# STM32H7B3x register map
File version: 2.2
CPU: CM7 r0p1, little endian, MPU, FPU, 4 interrupt priority bits
Registers are 32-bit, read-write, reset 0x0 unless marked. A register's access mark holds for its fields unless they carry their own. Offsets are from the block's base; [hi:lo] are bit positions; lines under a group give offsets from that group; {n}, {i} and the like mark numbered series; 'fields as' and 'values as' point back to an identical list; <NAME> marks a mode.

## DMA1 — DMA controller
Base 0x40020000
Same registers: DMA2 0x40020400
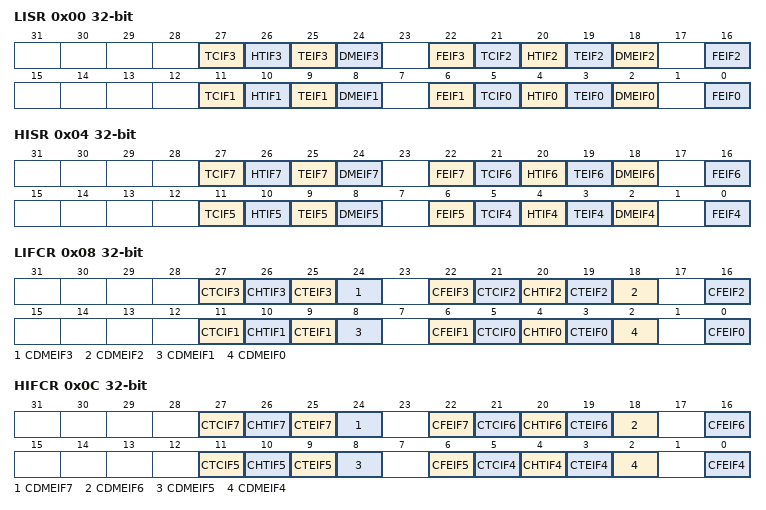
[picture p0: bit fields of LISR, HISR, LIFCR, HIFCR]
0x00 LISR ro — low interrupt status register
  [27] TCIF3 — Stream x transfer complete interrupt flag (x = 3..0)
    on read: 0=NotComplete (No transfer complete event on stream x); 1=Complete (A transfer complete event occurred on stream x)
  [26] HTIF3 — Stream x half transfer interrupt flag (x=3..0)
    on read: 0=NotHalf (No half transfer event on stream x); 1=Half (A half transfer event occurred on stream x)
  [25] TEIF3 — Stream x transfer error interrupt flag (x=3..0)
    on read: 0=NoError (No transfer error on stream x); 1=Error (A transfer error occurred on stream x)
  [24] DMEIF3 — Stream x direct mode error interrupt flag (x=3..0)
    on read: 0=NoError (No Direct Mode error on stream x); 1=Error (A Direct Mode error occurred on stream x)
  [22] FEIF3 — Stream x FIFO error interrupt flag (x=3..0)
    on read: 0=NoError (No FIFO error event on stream x); 1=Error (A FIFO error event occurred on stream x)
  [21] TCIF2 — Stream x transfer complete interrupt flag (x = 3..0)
    values as TCIF3
  [20] HTIF2 — Stream x half transfer interrupt flag (x=3..0)
    values as HTIF3
  [19] TEIF2 — Stream x transfer error interrupt flag (x=3..0)
    values as TEIF3
  [18] DMEIF2 — Stream x direct mode error interrupt flag (x=3..0)
    values as DMEIF3
  [16] FEIF2 — Stream x FIFO error interrupt flag (x=3..0)
    values as FEIF3
  [11] TCIF1 — Stream x transfer complete interrupt flag (x = 3..0)
    values as TCIF3
  [10] HTIF1 — Stream x half transfer interrupt flag (x=3..0)
    values as HTIF3
  [9] TEIF1 — Stream x transfer error interrupt flag (x=3..0)
    values as TEIF3
  [8] DMEIF1 — Stream x direct mode error interrupt flag (x=3..0)
    values as DMEIF3
  [6] FEIF1 — Stream x FIFO error interrupt flag (x=3..0)
    values as FEIF3
  [5] TCIF0 — Stream x transfer complete interrupt flag (x = 3..0)
    values as TCIF3
  [4] HTIF0 — Stream x half transfer interrupt flag (x=3..0)
    values as HTIF3
  [3] TEIF0 — Stream x transfer error interrupt flag (x=3..0)
    values as TEIF3
  [2] DMEIF0 — Stream x direct mode error interrupt flag (x=3..0)
    values as DMEIF3
  [0] FEIF0 — Stream x FIFO error interrupt flag (x=3..0)
    values as FEIF3
0x04 HISR ro — high interrupt status register
  [27] TCIF7 — Stream x transfer complete interrupt flag (x=7..4)
    values as LISR.TCIF3
  [26] HTIF7 — Stream x half transfer interrupt flag (x=7..4)
    values as LISR.HTIF3
  [25] TEIF7 — Stream x transfer error interrupt flag (x=7..4)
    values as LISR.TEIF3
  [24] DMEIF7 — Stream x direct mode error interrupt flag (x=7..4)
    values as LISR.DMEIF3
  [22] FEIF7 — Stream x FIFO error interrupt flag (x=7..4)
    values as LISR.FEIF3
  [21] TCIF6 — Stream x transfer complete interrupt flag (x=7..4)
    values as LISR.TCIF3
  [20] HTIF6 — Stream x half transfer interrupt flag (x=7..4)
    values as LISR.HTIF3
  [19] TEIF6 — Stream x transfer error interrupt flag (x=7..4)
    values as LISR.TEIF3
  [18] DMEIF6 — Stream x direct mode error interrupt flag (x=7..4)
    values as LISR.DMEIF3
  [16] FEIF6 — Stream x FIFO error interrupt flag (x=7..4)
    values as LISR.FEIF3
  [11] TCIF5 — Stream x transfer complete interrupt flag (x=7..4)
    values as LISR.TCIF3
  [10] HTIF5 — Stream x half transfer interrupt flag (x=7..4)
    values as LISR.HTIF3
  [9] TEIF5 — Stream x transfer error interrupt flag (x=7..4)
    values as LISR.TEIF3
  [8] DMEIF5 — Stream x direct mode error interrupt flag (x=7..4)
    values as LISR.DMEIF3
  [6] FEIF5 — Stream x FIFO error interrupt flag (x=7..4)
    values as LISR.FEIF3
  [5] TCIF4 — Stream x transfer complete interrupt flag (x=7..4)
    values as LISR.TCIF3
  [4] HTIF4 — Stream x half transfer interrupt flag (x=7..4)
    values as LISR.HTIF3
  [3] TEIF4 — Stream x transfer error interrupt flag (x=7..4)
    values as LISR.TEIF3
  [2] DMEIF4 — Stream x direct mode error interrupt flag (x=7..4)
    values as LISR.DMEIF3
  [0] FEIF4 — Stream x FIFO error interrupt flag (x=7..4)
    values as LISR.FEIF3
0x08 LIFCR wo — low interrupt flag clear register
  [27] CTCIF3 — Stream x clear transfer complete interrupt flag (x = 3..0)
    on write: 1=Clear the corresponding TCIFx flag
  [26] CHTIF3 — Stream x clear half transfer interrupt flag (x = 3..0)
    on write: 1=Clear the corresponding HTIFx flag
  [25] CTEIF3 — Stream x clear transfer error interrupt flag (x = 3..0)
    on write: 1=Clear the corresponding TEIFx flag
  [24] CDMEIF3 — Stream x clear direct mode error interrupt flag (x = 3..0)
    on write: 1=Clear the corresponding DMEIFx flag
  [22] CFEIF3 — Stream x clear FIFO error interrupt flag (x = 3..0)
    on write: 1=Clear the corresponding CFEIFx flag
  [21] CTCIF2 — Stream x clear transfer complete interrupt flag (x = 3..0)
    on write: 1=Clear the corresponding TCIFx flag
  [20] CHTIF2 — Stream x clear half transfer interrupt flag (x = 3..0)
    on write: 1=Clear the corresponding HTIFx flag
  [19] CTEIF2 — Stream x clear transfer error interrupt flag (x = 3..0)
    on write: 1=Clear the corresponding TEIFx flag
  [18] CDMEIF2 — Stream x clear direct mode error interrupt flag (x = 3..0)
    on write: 1=Clear the corresponding DMEIFx flag
  [16] CFEIF2 — Stream x clear FIFO error interrupt flag (x = 3..0)
    on write: 1=Clear the corresponding CFEIFx flag
  [11] CTCIF1 — Stream x clear transfer complete interrupt flag (x = 3..0)
    on write: 1=Clear the corresponding TCIFx flag
  [10] CHTIF1 — Stream x clear half transfer interrupt flag (x = 3..0)
    on write: 1=Clear the corresponding HTIFx flag
  [9] CTEIF1 — Stream x clear transfer error interrupt flag (x = 3..0)
    on write: 1=Clear the corresponding TEIFx flag
  [8] CDMEIF1 — Stream x clear direct mode error interrupt flag (x = 3..0)
    on write: 1=Clear the corresponding DMEIFx flag
  [6] CFEIF1 — Stream x clear FIFO error interrupt flag (x = 3..0)
    on write: 1=Clear the corresponding CFEIFx flag
  [5] CTCIF0 — Stream x clear transfer complete interrupt flag (x = 3..0)
    on write: 1=Clear the corresponding TCIFx flag
  [4] CHTIF0 — Stream x clear half transfer interrupt flag (x = 3..0)
    on write: 1=Clear the corresponding HTIFx flag
  [3] CTEIF0 — Stream x clear transfer error interrupt flag (x = 3..0)
    on write: 1=Clear the corresponding TEIFx flag
  [2] CDMEIF0 — Stream x clear direct mode error interrupt flag (x = 3..0)
    on write: 1=Clear the corresponding DMEIFx flag
  [0] CFEIF0 — Stream x clear FIFO error interrupt flag (x = 3..0)
    on write: 1=Clear the corresponding CFEIFx flag
0x0C HIFCR wo — high interrupt flag clear register
  [27] CTCIF7 — Stream x clear transfer complete interrupt flag (x = 7..4)
    on write: 1=Clear the corresponding TCIFx flag
  [26] CHTIF7 — Stream x clear half transfer interrupt flag (x = 7..4)
    on write: 1=Clear the corresponding HTIFx flag
  [25] CTEIF7 — Stream x clear transfer error interrupt flag (x = 7..4)
    on write: 1=Clear the corresponding TEIFx flag
  [24] CDMEIF7 — Stream x clear direct mode error interrupt flag (x = 7..4)
    on write: 1=Clear the corresponding DMEIFx flag
  [22] CFEIF7 — Stream x clear FIFO error interrupt flag (x = 7..4)
    on write: 1=Clear the corresponding CFEIFx flag
  [21] CTCIF6 — Stream x clear transfer complete interrupt flag (x = 7..4)
    on write: 1=Clear the corresponding TCIFx flag
  [20] CHTIF6 — Stream x clear half transfer interrupt flag (x = 7..4)
    on write: 1=Clear the corresponding HTIFx flag
  [19] CTEIF6 — Stream x clear transfer error interrupt flag (x = 7..4)
    on write: 1=Clear the corresponding TEIFx flag
  [18] CDMEIF6 — Stream x clear direct mode error interrupt flag (x = 7..4)
    on write: 1=Clear the corresponding DMEIFx flag
  [16] CFEIF6 — Stream x clear FIFO error interrupt flag (x = 7..4)
    on write: 1=Clear the corresponding CFEIFx flag
  [11] CTCIF5 — Stream x clear transfer complete interrupt flag (x = 7..4)
    on write: 1=Clear the corresponding TCIFx flag
  [10] CHTIF5 — Stream x clear half transfer interrupt flag (x = 7..4)
    on write: 1=Clear the corresponding HTIFx flag
  [9] CTEIF5 — Stream x clear transfer error interrupt flag (x = 7..4)
    on write: 1=Clear the corresponding TEIFx flag
  [8] CDMEIF5 — Stream x clear direct mode error interrupt flag (x = 7..4)
    on write: 1=Clear the corresponding DMEIFx flag
  [6] CFEIF5 — Stream x clear FIFO error interrupt flag (x = 7..4)
    on write: 1=Clear the corresponding CFEIFx flag
  [5] CTCIF4 — Stream x clear transfer complete interrupt flag (x = 7..4)
    on write: 1=Clear the corresponding TCIFx flag
  [4] CHTIF4 — Stream x clear half transfer interrupt flag (x = 7..4)
    on write: 1=Clear the corresponding HTIFx flag
  [3] CTEIF4 — Stream x clear transfer error interrupt flag (x = 7..4)
    on write: 1=Clear the corresponding TEIFx flag
  [2] CDMEIF4 — Stream x clear direct mode error interrupt flag (x = 7..4)
    on write: 1=Clear the corresponding DMEIFx flag
  [0] CFEIF4 — Stream x clear FIFO error interrupt flag (x = 7..4)
    on write: 1=Clear the corresponding CFEIFx flag
{0x10+0x18*i} ST{i} (i=0..7) group — Stream cluster: S?CR, S?NDTR, S?M0AR, S?M1AR and S?FCR registers
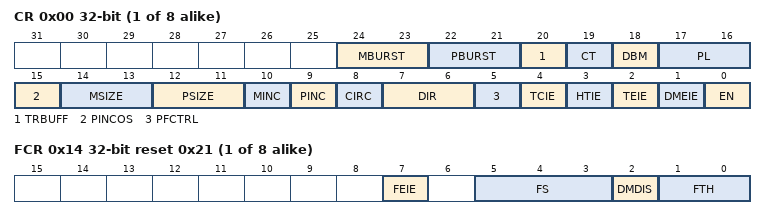
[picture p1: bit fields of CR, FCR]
  0x00 CR — stream x configuration register
    [24:23] MBURST — Memory burst transfer configuration
      0=Single transfer; 1=INCR4 (Incremental burst of 4 beats); 2=INCR8 (Incremental burst of 8 beats); 3=INCR16 (Incremental burst of 16 beats)
    [22:21] PBURST — Peripheral burst transfer configuration
      values as MBURST
    [20] TRBUFF — Enable the DMA to handle bufferable transfers
      0=Disabled (Bufferable transfers not enabled); 1=Enabled (Bufferable transfers enabled)
    [19] CT — Current target (only in double buffer mode)
      0=Memory0 (The current target memory is Memory 0); 1=Memory1 (The current target memory is Memory 1)
    [18] DBM — Double buffer mode
      0=Disabled (No buffer switching at the end of transfer); 1=Enabled (Memory target switched at the end of the DMA transfer)
    [17:16] PL — Priority level
      0=Low; 1=Medium; 2=High; 3=VeryHigh
    [15] PINCOS — Peripheral increment offset size
      0=PSIZE (The offset size for the peripheral address calculation is linked to the PSIZE); 1=Fixed4 (The offset size for the peripheral address calculation is fixed to 4 (32-bit alignment))
    [14:13] MSIZE — Memory data size
      0=Bits8 (Byte (8-bit)); 1=Bits16 (Half-word (16-bit)); 2=Bits32 (Word (32-bit))
    [12:11] PSIZE — Peripheral data size
      values as MSIZE
    [10] MINC — Memory increment mode
      0=Fixed (Address pointer is fixed); 1=Incremented (Address pointer is incremented after each data transfer)
    [9] PINC — Peripheral increment mode
      values as MINC
    [8] CIRC — Circular mode
      0=Disabled (Circular mode disabled); 1=Enabled (Circular mode enabled)
    [7:6] DIR — Data transfer direction
      0=PeripheralToMemory; 1=MemoryToPeripheral; 2=MemoryToMemory
    [5] PFCTRL — Peripheral flow controller
      0=DMA (The DMA is the flow controller); 1=Peripheral (The peripheral is the flow controller)
    [4] TCIE — Transfer complete interrupt enable
      0=Disabled (TC interrupt disabled); 1=Enabled (TC interrupt enabled)
    [3] HTIE — Half transfer interrupt enable
      0=Disabled (HT interrupt disabled); 1=Enabled (HT interrupt enabled)
    [2] TEIE — Transfer error interrupt enable
      0=Disabled (TE interrupt disabled); 1=Enabled (TE interrupt enabled)
    [1] DMEIE — Direct mode error interrupt enable
      0=Disabled (DME interrupt disabled); 1=Enabled (DME interrupt enabled)
    [0] EN — Stream enable / flag stream ready when read low
      0=Disabled (Stream disabled); 1=Enabled (Stream enabled)
  0x04 NDTR — stream x number of data register
    [15:0] NDT — Number of data items to transfer
  0x08 PAR — stream x peripheral address register
    [31:0] PA — Peripheral address
  0x0C M0AR — stream x memory 0 address register
    [31:0] M0A — Memory 0 address
  0x10 M1AR — stream x memory 1 address register
    [31:0] M1A — Memory 1 address (used in case of Double buffer mode)
  0x14 FCR access per field reset 0x21 — stream x FIFO control register
    [7] FEIE rw — FIFO error interrupt enable
      0=Disabled (FE interrupt disabled); 1=Enabled (FE interrupt enabled)
    [5:3] FS ro — FIFO status
      on read: 0=Quarter1 (0 < fifo_level < 1/4); 1=Quarter2 (1/4 <= fifo_level < 1/2); 2=Quarter3 (1/2 <= fifo_level < 3/4); 3=Quarter4 (3/4 <= fifo_level < full); 4=Empty (FIFO is empty); 5=Full (FIFO is full)
    [2] DMDIS rw — Direct mode disable
      0=Enabled (Direct mode is enabled); 1=Disabled (Direct mode is disabled)
    [1:0] FTH rw — FIFO threshold selection
      0=Quarter (1/4 full FIFO); 1=Half (1/2 full FIFO); 2=ThreeQuarters (3/4 full FIFO); 3=Full FIFO
